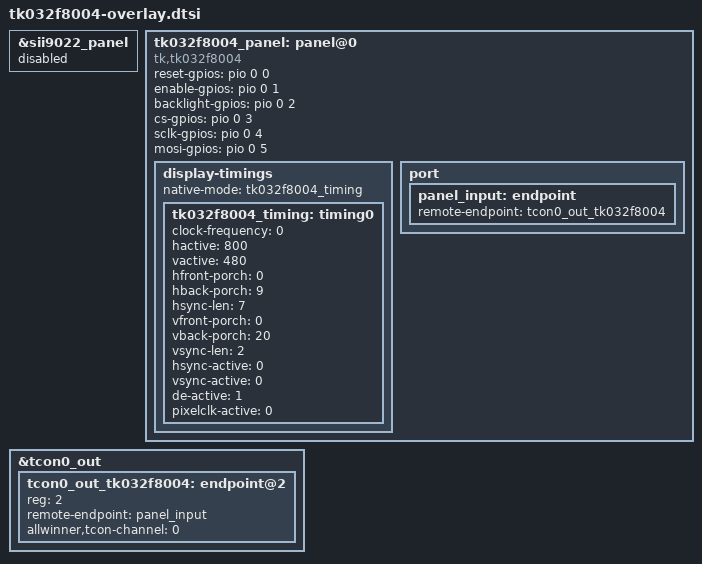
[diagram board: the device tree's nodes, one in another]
/* Candidate only: merge into the active board DTS on a dedicated branch. */

&sii9022_panel {
	status = "disabled";
};

tk032f8004_panel: panel@0 {
	compatible = "tk,tk032f8004";
	status = "okay";

	/* Replace each GPIO specifier with the verified F1C200S wiring. */
	reset-gpios = <&pio 0 0 GPIO_ACTIVE_HIGH>;
	enable-gpios = <&pio 0 1 GPIO_ACTIVE_HIGH>;
	backlight-gpios = <&pio 0 2 GPIO_ACTIVE_HIGH>;
	cs-gpios = <&pio 0 3 GPIO_ACTIVE_HIGH>;
	sclk-gpios = <&pio 0 4 GPIO_ACTIVE_HIGH>;
	mosi-gpios = <&pio 0 5 GPIO_ACTIVE_HIGH>;

	display-timings {
		native-mode = <&tk032f8004_timing>;
		tk032f8004_timing: timing0 {
			/* Verified target orientation: 800x480 landscape. */
			clock-frequency = <0>; /* Confirm panel PCLK before DTS compilation. */
			hactive = <800>;
			vactive = <480>;
			/* TK499 timing axes are transposed for the landscape TCON output. */
			hfront-porch = <0>;
			hback-porch = <9>;
			hsync-len = <7>;
			vfront-porch = <0>;
			vback-porch = <20>;
			vsync-len = <2>;
			hsync-active = <0>;
			vsync-active = <0>;
			de-active = <1>;
			pixelclk-active = <0>;
		};
	};

	port {
		panel_input: endpoint {
			remote-endpoint = <&tcon0_out_tk032f8004>;
		};
	};
};

&tcon0_out {
	tcon0_out_tk032f8004: endpoint@2 {
		reg = <2>;
		remote-endpoint = <&panel_input>;
		allwinner,tcon-channel = <0>;
	};
};
